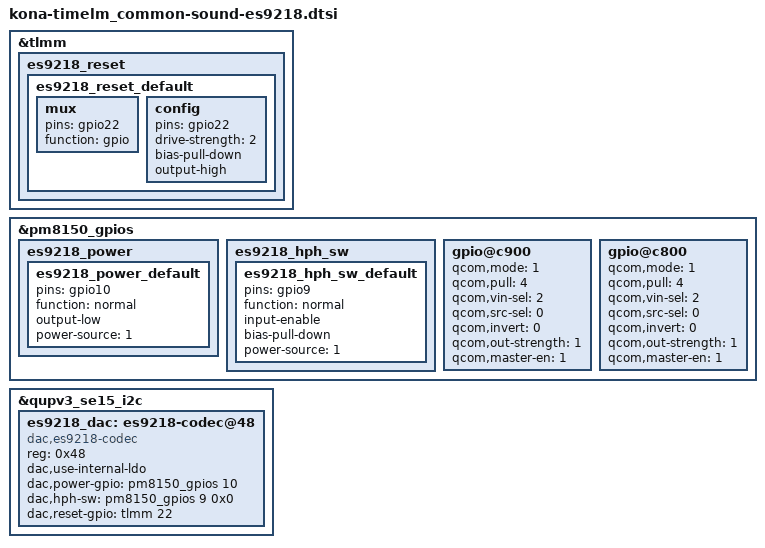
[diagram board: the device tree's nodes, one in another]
/*
 * Copyright (c) 2018, The Linux Foundation. All rights reserved.
 *
 * This program is free software; you can redistribute it and/or modify
 * it under the terms of the GNU General Public License version 2 and
 * only version 2 as published by the Free Software Foundation.
 *
 * This program is distributed in the hope that it will be useful,
 * but WITHOUT ANY WARRANTY; without even the implied warranty of
 * MERCHANTABILITY or FITNESS FOR A PARTICULAR PURPOSE.  See the
 * GNU General Public License for more details.
 */

&tlmm {
	es9218_reset {
		es9218_reset_default: es9218_reset_default {
			mux {
				pins = "gpio22";
				function = "gpio";
			};

			config {
				pins = "gpio22";
				drive-strength = <2>;
				bias-pull-down;
				output-high;
			};
		};
	};
};

&pm8150_gpios {
	es9218_power {
		es9218_power_default: es9218_power_default {
			pins = "gpio10";
			function = "normal";
			output-low;
			power-source = <1>;	/* 1.8V input supply */
		};
	};

	es9218_hph_sw {
		es9218_hph_sw_default: es9218_hph_sw_default {
			pins = "gpio9";
			function = "normal";
			input-enable;
			bias-pull-down;
			power-source = <1>;	/* 1.8V input supply */
		};
	};
};
	
&qupv3_se15_i2c{ /* QUPV3 SE15  */
	status = "ok";

	es9218_dac: es9218-codec@48{
		compatible = "dac,es9218-codec";
		status = "ok";
		reg = <0x48>;
		dac,use-internal-ldo;
		dac,power-gpio = <&pm8150_gpios 10 0x0>;
		dac,hph-sw = <&pm8150_gpios 9 0x0>;
		dac,reset-gpio = <&tlmm 22 0x0>;

//		pinctrl-names = "default";
//		pinctrl-0 = <&es9218_power_default>,<&es9218_hph_sw_default>,<&es9218_reset_default>;

	};
};

&pm8150_gpios {
	gpio@c900 { /* GPIO 10 - HIFI_LDO_SW */
		qcom,mode = <1>;			/* Digital output */
		qcom,pull = <4>;			/* Pull down */
		qcom,vin-sel = <2>;			/* Vin2 */
		qcom,src-sel = <0>;			/* Constant */
		qcom,invert = <0>;			/* Disable Invert */
		qcom,out-strength = <1>;	/* Low */
		qcom,master-en = <1>;		/* Disable GPIO */
		status = "okay";
	};

	gpio@c800 { /* GPIO 9 - HIFI_MODE2 */
		qcom,mode = <1>;			/* Digital output */
		qcom,pull = <4>;			/* Pull down */
		qcom,vin-sel = <2>;			/* Vin 2 */
		qcom,src-sel = <0>;			/* Constant */
		qcom,invert = <0>;			/* Invert */
		qcom,out-strength = <1>;	/* Low */
		qcom,master-en = <1>;		/* Enable GPIO */
		status = "okay";
	};
};

